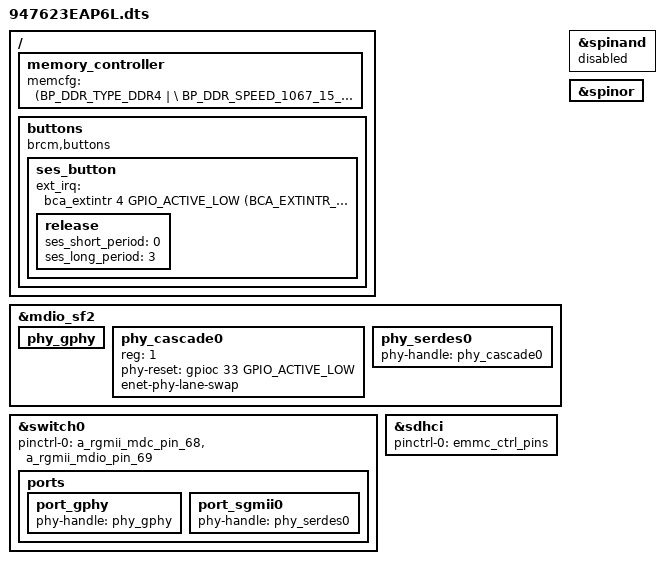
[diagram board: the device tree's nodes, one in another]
#include "6756.dtsi"

/ {
	memory_controller {
		memcfg = <(BP_DDR_TYPE_DDR4           | \
			BP_DDR_SPEED_1067_15_15_15 | \
			BP_DDR_TOTAL_SIZE_2048MB   | \
			BP_DDR_DEVICE_WIDTH_8      | \
			BP_DDR_TOTAL_WIDTH_16BIT   | \
			BP_DDR_6756_DEFAULT          | \
			BP_DDR_CONFIG_DEBUG)>;
	};

	buttons {
		compatible = "brcm,buttons";
		ses_button {
			ext_irq = <&bca_extintr 4 GPIO_ACTIVE_LOW (BCA_EXTINTR_TYPE_LOW_LEVEL | BCA_EXTINTR_TYPE_SENSE_EDGE)>;
			release {
				ses_short_period = <0>;
				ses_long_period = <3>;
			};
		};
	};
};


&mdio_sf2 {
   /* Port PHY mapping:
        port_imp -8#0- port_gphy <---> phy_gphy
                  ##5- port_sgmii0 <-> phy_serdes0 - phy_casade0
     */
	phy_gphy {
		status = "okay";
	};
	phy_cascade0 {
		reg = <1>;
		phy-reset = <&gpioc 33 GPIO_ACTIVE_LOW>;
		enet-phy-lane-swap;
		status = "okay";
	};
	phy_serdes0 {
		phy-handle = <&phy_cascade0>;
		status = "okay";    /* HSGMII 5GE */
	};
};

&switch0 {
	pinctrl-names = "default"; 
	pinctrl-0 = <&a_rgmii_mdc_pin_68 &a_rgmii_mdio_pin_69>; 

	ports {
		port_gphy {
			phy-handle = <&phy_gphy>;
			status = "okay";
		};
		port_sgmii0 {
			phy-handle = <&phy_serdes0>;
			status = "okay";
		};
	};
};

&sdhci {
	pinctrl-names="default";
	pinctrl-0 = <&emmc_ctrl_pins>;
	status = "okay";
};

&spinand {
	status = "disabled";
};

&spinor {
	status = "okay";
};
